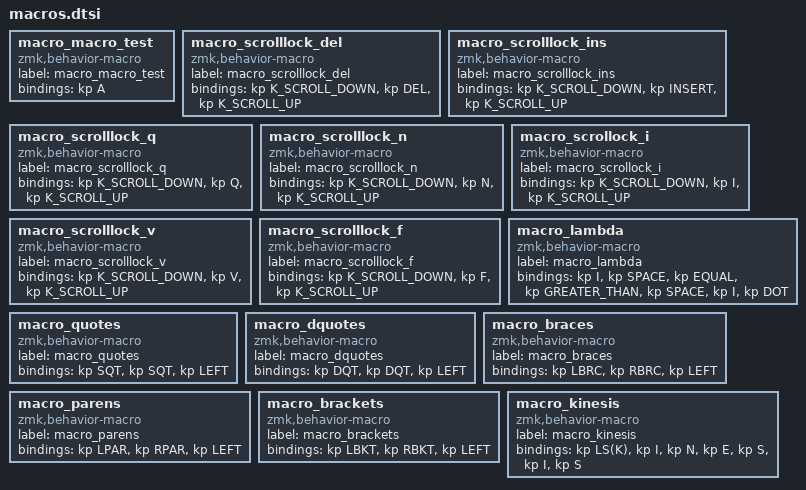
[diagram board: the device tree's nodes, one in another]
macro_macro_test: macro_macro_test{
compatible = "zmk,behavior-macro";
label = "macro_macro_test";
#binding-cells = <0>;
bindings = <&kp A>;
};
macro_scrolllock_del: macro_scrolllock_del{
compatible = "zmk,behavior-macro";
label = "macro_scrolllock_del";
#binding-cells = <0>;
bindings = <&kp K_SCROLL_DOWN>, <&kp DEL>, <&kp K_SCROLL_UP>;
};
macro_scrolllock_ins: macro_scrolllock_ins{
compatible = "zmk,behavior-macro";
label = "macro_scrolllock_ins";
#binding-cells = <0>;
bindings = <&kp K_SCROLL_DOWN>, <&kp INSERT>, <&kp K_SCROLL_UP>;
};
macro_scrolllock_q: macro_scrolllock_q{
compatible = "zmk,behavior-macro";
label = "macro_scrolllock_q";
#binding-cells = <0>;
bindings = <&kp K_SCROLL_DOWN>, <&kp Q>, <&kp K_SCROLL_UP>;
};
macro_scrolllock_n: macro_scrolllock_n{
compatible = "zmk,behavior-macro";
label = "macro_scrolllock_n";
#binding-cells = <0>;
bindings = <&kp K_SCROLL_DOWN>, <&kp N>, <&kp K_SCROLL_UP>;
};
macro_scrollock_i: macro_scrollock_i{
compatible = "zmk,behavior-macro";
label = "macro_scrollock_i";
#binding-cells = <0>;
bindings = <&kp K_SCROLL_DOWN>, <&kp I>, <&kp K_SCROLL_UP>;
};
macro_scrolllock_v: macro_scrolllock_v{
compatible = "zmk,behavior-macro";
label = "macro_scrolllock_v";
#binding-cells = <0>;
bindings = <&kp K_SCROLL_DOWN>, <&kp V>, <&kp K_SCROLL_UP>;
};
macro_scrolllock_f: macro_scrolllock_f{
compatible = "zmk,behavior-macro";
label = "macro_scrolllock_f";
#binding-cells = <0>;
bindings = <&kp K_SCROLL_DOWN>, <&kp F>, <&kp K_SCROLL_UP>;
};
macro_lambda: macro_lambda{
compatible = "zmk,behavior-macro";
label = "macro_lambda";
#binding-cells = <0>;
bindings = <&kp I>, <&kp SPACE>, <&kp EQUAL>, <&kp GREATER_THAN>, <&kp SPACE>, <&kp I>, <&kp DOT>;
};
macro_quotes: macro_quotes{
compatible = "zmk,behavior-macro";
label = "macro_quotes";
#binding-cells = <0>;
bindings = <&kp SQT>, <&kp SQT>, <&kp LEFT>;
};
macro_dquotes: macro_dquotes{
compatible = "zmk,behavior-macro";
label = "macro_dquotes";
#binding-cells = <0>;
bindings = <&kp DQT>, <&kp DQT>, <&kp LEFT>;
};
macro_braces: macro_braces{
compatible = "zmk,behavior-macro";
label = "macro_braces";
#binding-cells = <0>;
bindings = <&kp LBRC>, <&kp RBRC>, <&kp LEFT>;
};
macro_parens: macro_parens{
compatible = "zmk,behavior-macro";
label = "macro_parens";
#binding-cells = <0>;
bindings = <&kp LPAR>, <&kp RPAR>, <&kp LEFT>;
};
macro_brackets: macro_brackets{
compatible = "zmk,behavior-macro";
label = "macro_brackets";
#binding-cells = <0>;
bindings = <&kp LBKT>, <&kp RBKT>, <&kp LEFT>;
};
macro_kinesis: macro_kinesis{
compatible = "zmk,behavior-macro";
label = "macro_kinesis";
#binding-cells = <0>;
bindings = <&kp LS(K)>, <&kp I>, <&kp N>, <&kp E>, <&kp S>, <&kp I>, <&kp S>;
};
